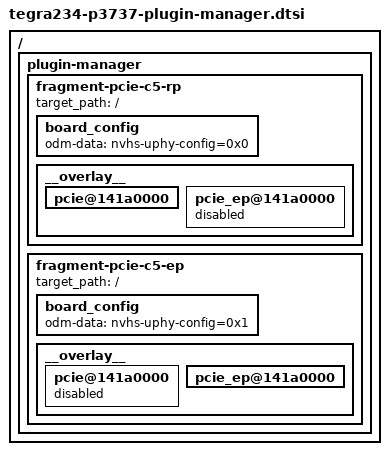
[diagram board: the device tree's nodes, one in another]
/*
 * Copyright (c) 2021, NVIDIA CORPORATION.  All rights reserved.
 *
 * This program is free software; you can redistribute it and/or modify
 * it under the terms of the GNU General Public License as published by
 * the Free Software Foundation; version 2 of the License.
 *
 * This program is distributed in the hope that it will be useful, but WITHOUT
 * ANY WARRANTY; without even the implied warranty of MERCHANTABILITY or
 * FITNESS FOR A PARTICULAR PURPOSE.  See the GNU General Public License for
 * more details.
 */

/ {
	plugin-manager {
		fragment-pcie-c5-rp {
			target_path = "/";
			board_config {
				odm-data = "nvhs-uphy-config=0x0";
			};
			__overlay__ {
				pcie@141a0000 {
					status = "okay";
				};
				pcie_ep@141a0000 {
					status = "disabled";
				};
			};
		};

		fragment-pcie-c5-ep {
			target_path = "/";
			board_config {
				odm-data = "nvhs-uphy-config=0x1";
			};
			__overlay__ {
				pcie@141a0000 {
					status = "disabled";
				};
				pcie_ep@141a0000 {
					status = "okay";
				};
			};
		};
	};
};
